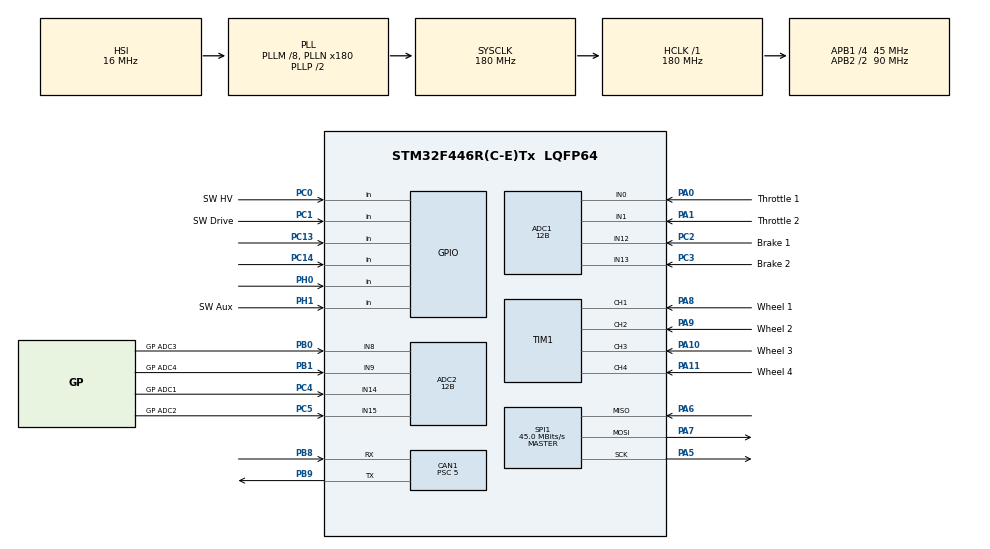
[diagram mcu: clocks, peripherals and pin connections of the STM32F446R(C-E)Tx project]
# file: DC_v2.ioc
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ADC1.Channel-52\#ChannelRegularConversion=ADC_CHANNEL_0
ADC1.Channel-53\#ChannelRegularConversion=ADC_CHANNEL_1
ADC1.Channel-54\#ChannelRegularConversion=ADC_CHANNEL_12
ADC1.Channel-55\#ChannelRegularConversion=ADC_CHANNEL_13
ADC1.ClockPrescaler=ADC_CLOCK_SYNC_PCLK_DIV4
ADC1.ContinuousConvMode=ENABLE
ADC1.DMAContinuousRequests=ENABLE
ADC1.DataAlign=ADC_DATAALIGN_RIGHT
ADC1.DiscontinuousConvMode=DISABLE
ADC1.EOCSelection=ADC_EOC_SEQ_CONV
ADC1.EnableAnalogWatchDog=false
ADC1.ExternalTrigConv=ADC_SOFTWARE_START
ADC1.ExternalTrigConvEdge=ADC_EXTERNALTRIGCONVEDGE_NONE
ADC1.InjNumberOfConversion=0
ADC1.NbrOfConversion=4
ADC1.NbrOfConversionFlag=1
ADC1.Rank-52\#ChannelRegularConversion=1
ADC1.Rank-53\#ChannelRegularConversion=2
ADC1.Rank-54\#ChannelRegularConversion=3
ADC1.Rank-55\#ChannelRegularConversion=4
ADC1.Resolution=ADC_RESOLUTION_12B
ADC1.SamplingTime-52\#ChannelRegularConversion=ADC_SAMPLETIME_3CYCLES
ADC1.SamplingTime-53\#ChannelRegularConversion=ADC_SAMPLETIME_3CYCLES
ADC1.SamplingTime-54\#ChannelRegularConversion=ADC_SAMPLETIME_3CYCLES
ADC1.SamplingTime-55\#ChannelRegularConversion=ADC_SAMPLETIME_3CYCLES
ADC1.ScanConvMode=ENABLE
ADC1.master=1
ADC2.Channel-152\#ChannelRegularConversion=ADC_CHANNEL_8
ADC2.ClockPrescaler=ADC_CLOCK_SYNC_PCLK_DIV4
ADC2.ContinuousConvMode=DISABLE
ADC2.DMAContinuousRequests=DISABLE
ADC2.DataAlign=ADC_DATAALIGN_RIGHT
ADC2.DiscontinuousConvMode=DISABLE
ADC2.EOCSelection=ADC_EOC_SINGLE_CONV
ADC2.EnableAnalogWatchDog=false
ADC2.ExternalTrigConv=ADC_SOFTWARE_START
ADC2.ExternalTrigConvEdge=ADC_EXTERNALTRIGCONVEDGE_NONE
ADC2.InjNumberOfConversion=0
ADC2.NbrOfConversion=1
ADC2.NbrOfConversionFlag=1
ADC2.Rank-152\#ChannelRegularConversion=1
ADC2.Resolution=ADC_RESOLUTION_12B
ADC2.SamplingTime-152\#ChannelRegularConversion=ADC_SAMPLETIME_3CYCLES
ADC2.ScanConvMode=DISABLE
CAN1.BS1=CAN_BS1_15TQ
CAN1.BS2=CAN_BS2_2TQ
CAN1.CalculateTimeBit=2000
CAN1.CalculateTimeQuantum=111.11111111111111
CAN1.Prescaler=5
Dma.ADC1.0.Direction=DMA_PERIPH_TO_MEMORY
Dma.ADC1.0.FIFOMode=DMA_FIFOMODE_DISABLE
Dma.ADC1.0.Instance=DMA2_Stream0
Dma.ADC1.0.MemDataAlignment=DMA_MDATAALIGN_HALFWORD
Dma.ADC1.0.MemInc=DMA_MINC_ENABLE
Dma.ADC1.0.Mode=DMA_CIRCULAR
Dma.ADC1.0.PeriphDataAlignment=DMA_PDATAALIGN_HALFWORD
Dma.ADC1.0.PeriphInc=DMA_PINC_DISABLE
Dma.ADC1.0.Priority=DMA_PRIORITY_HIGH
Dma.Request0=ADC1
FREERTOS.Tasks01=defaultTask,-3,128,StartDefaultTask,Default,NULL,Dynamic,NULL,NULL
Mcu.Family=STM32F4
Mcu.Name=STM32F446R(C-E)Tx
Mcu.Package=LQFP64
NVIC.DMA2_Stream0_IRQn=true\:5\:0\:false\:false\:true\:true
NVIC.PriorityGroup=NVIC_PRIORITYGROUP_4
PA0-WKUP.GPIO_Label=Throttle 1
PA0-WKUP.Signal=ADCx_IN0
PA1.GPIO_Label=Throttle 2
PA1.Signal=ADCx_IN1
PA10.GPIO_Label=Wheel 3
PA10.Signal=S_TIM1_CH3
PA11.GPIO_Label=Wheel 4
PA11.Signal=S_TIM1_CH4
PA5.Mode=Full_Duplex_Master
PA5.Signal=SPI1_SCK
PA6.Mode=Full_Duplex_Master
PA6.Signal=SPI1_MISO
PA7.Mode=Full_Duplex_Master
PA7.Signal=SPI1_MOSI
PA8.GPIO_Label=Wheel 1
PA8.Signal=S_TIM1_CH1
PA9.GPIO_Label=Wheel 2
PA9.Signal=S_TIM1_CH2
PB0.GPIO_Label=GP ADC3
PB0.Signal=ADCx_IN8
PB1.GPIO_Label=GP ADC4
PB1.Signal=ADCx_IN9
PB8.Mode=Master
PB8.Signal=CAN1_RX
PB9.Mode=Master
PB9.Signal=CAN1_TX
PC0.GPIO_Label=SW HV
PC0.Signal=GPIO_Input
PC1.GPIO_Label=SW Drive
PC1.Signal=GPIO_Input
PC13.Signal=GPIO_Input
PC14-OSC32_IN.Signal=GPIO_Input
PC2.GPIO_Label=Brake 1
PC2.Signal=ADCx_IN12
PC3.GPIO_Label=Brake 2
PC3.Signal=ADCx_IN13
PC4.GPIO_Label=GP ADC1
PC4.Signal=ADCx_IN14
PC5.GPIO_Label=GP ADC2
PC5.Signal=ADCx_IN15
PH0-OSC_IN.Signal=GPIO_Input
PH1-OSC_OUT.GPIO_Label=SW Aux
PH1-OSC_OUT.GPIO_Mode=GPIO_MODE_INPUT
PH1-OSC_OUT.GPIO_PuPd=GPIO_NOPULL
PH1-OSC_OUT.Signal=GPIO_Input
ProjectManager.HeapSize=0x200
ProjectManager.StackSize=0x400
ProjectManager.TargetToolchain=SW4STM32
RCC.AHBFreq_Value=180000000
RCC.APB1CLKDivider=RCC_HCLK_DIV4
RCC.APB1Freq_Value=45000000
RCC.APB1TimFreq_Value=90000000
RCC.APB2CLKDivider=RCC_HCLK_DIV2
RCC.APB2Freq_Value=90000000
RCC.APB2TimFreq_Value=180000000
RCC.CortexFreq_Value=180000000
RCC.HCLKFreq_Value=180000000
RCC.PLLM=8
RCC.PLLN=180
RCC.SYSCLKFreq_VALUE=180000000
RCC.SYSCLKSource=RCC_SYSCLKSOURCE_PLLCLK
RCC.USBFreq_Value=180000000
RCC.VCOOutputFreq_Value=360000000
SH.ADCx_IN0.0=ADC1_IN0,IN0
SH.ADCx_IN1.0=ADC1_IN1,IN1
SH.ADCx_IN12.0=ADC1_IN12,IN12
SH.ADCx_IN13.0=ADC1_IN13,IN13
SH.ADCx_IN14.0=ADC2_IN14,IN14
SH.ADCx_IN15.0=ADC2_IN15,IN15
SH.ADCx_IN8.0=ADC2_IN8,IN8
SH.ADCx_IN9.0=ADC2_IN9,IN9
SH.S_TIM1_CH1.0=TIM1_CH1,Input_Capture1_from_TI1
SH.S_TIM1_CH2.0=TIM1_CH2,Input_Capture2_from_TI2
SH.S_TIM1_CH3.0=TIM1_CH3,Input_Capture3_from_TI3
SH.S_TIM1_CH4.0=TIM1_CH4,Input_Capture4_from_TI4
SPI1.CalculateBaudRate=45.0 MBits/s
SPI1.Direction=SPI_DIRECTION_2LINES
SPI1.Mode=SPI_MODE_MASTER
SPI1.VirtualType=VM_MASTER
TIM1.Channel-Input_Capture1_from_TI1=TIM_CHANNEL_1
TIM1.Channel-Input_Capture2_from_TI2=TIM_CHANNEL_2
TIM1.Channel-Input_Capture3_from_TI3=TIM_CHANNEL_3
TIM1.Channel-Input_Capture4_from_TI4=TIM_CHANNEL_4
VP_FREERTOS_VS_ENABLE.Mode=Enabled
board=DC_v2

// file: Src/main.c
/**
  ******************************************************************************
  * File Name          : main.c
  * Description        : Main program body
  ******************************************************************************
  * This notice applies to any and all portions of this file
  * that are not between comment pairs USER CODE BEGIN and
  * USER CODE END. Other portions of this file, whether
  * inserted by the user or by software development tools
  * are owned by their respective copyright owners.
  *
  * Copyright (c) 2017 STMicroelectronics International N.V.
  * All rights reserved.
  *
  * Redistribution and use in source and binary forms, with or without
  * modification, are permitted, provided that the following conditions are met:
  *
  * 1. Redistribution of source code must retain the above copyright notice,
  *    this list of conditions and the following disclaimer.
  * 2. Redistributions in binary form must reproduce the above copyright notice,
  *    this list of conditions and the following disclaimer in the documentation
  *    and/or other materials provided with the distribution.
  * 3. Neither the name of STMicroelectronics nor the names of other
  *    contributors to this software may be used to endorse or promote products
  *    derived from this software without specific written permission.
  * 4. This software, including modifications and/or derivative works of this
  *    software, must execute solely and exclusively on microcontroller or
  *    microprocessor devices manufactured by or for STMicroelectronics.
  * 5. Redistribution and use of this software other than as permitted under
  *    this license is void and will automatically terminate your rights under
  *    this license.
  *
  * THIS SOFTWARE IS PROVIDED BY STMICROELECTRONICS AND CONTRIBUTORS "AS IS"
  * AND ANY EXPRESS, IMPLIED OR STATUTORY WARRANTIES, INCLUDING, BUT NOT
  * LIMITED TO, THE IMPLIED WARRANTIES OF MERCHANTABILITY, FITNESS FOR A
  * PARTICULAR PURPOSE AND NON-INFRINGEMENT OF THIRD PARTY INTELLECTUAL PROPERTY
  * RIGHTS ARE DISCLAIMED TO THE FULLEST EXTENT PERMITTED BY LAW. IN NO EVENT
  * SHALL STMICROELECTRONICS OR CONTRIBUTORS BE LIABLE FOR ANY DIRECT, INDIRECT,
  * INCIDENTAL, SPECIAL, EXEMPLARY, OR CONSEQUENTIAL DAMAGES (INCLUDING, BUT NOT
  * LIMITED TO, PROCUREMENT OF SUBSTITUTE GOODS OR SERVICES; LOSS OF USE, DATA,
  * OR PROFITS; OR BUSINESS INTERRUPTION) HOWEVER CAUSED AND ON ANY THEORY OF
  * LIABILITY, WHETHER IN CONTRACT, STRICT LIABILITY, OR TORT (INCLUDING
  * NEGLIGENCE OR OTHERWISE) ARISING IN ANY WAY OUT OF THE USE OF THIS SOFTWARE,
  * EVEN IF ADVISED OF THE POSSIBILITY OF SUCH DAMAGE.
  *
  ******************************************************************************
  */
#include "main.h"
#include "stm32f4xx_hal.h"
#include "cmsis_os.h"

/* USER CODE BEGIN Includes */
#include "debug.h"
#include "pedal.h"
/* USER CODE END Includes */

ADC_HandleTypeDef hadc1;
ADC_HandleTypeDef hadc2;
DMA_HandleTypeDef hdma_adc1;

CAN_HandleTypeDef hcan1;

SPI_HandleTypeDef hspi1;

TIM_HandleTypeDef htim1;

osThreadId defaultTaskHandle;

/* USER CODE BEGIN PV */
/* Private variables ---------------------------------------------------------*/

/* USER CODE END PV */

void SystemClock_Config(void);
static void MX_GPIO_Init(void);
static void MX_DMA_Init(void);
static void MX_ADC1_Init(void);
static void MX_ADC2_Init(void);
static void MX_CAN1_Init(void);
static void MX_SPI1_Init(void);
static void MX_TIM1_Init(void);
void StartDefaultTask(void const * argument);

/* USER CODE BEGIN PFP */
/* Private function prototypes -----------------------------------------------*/

/* USER CODE END PFP */

int main(void)
{

  /* MCU Configuration----------------------------------------------------------*/

  /* Reset of all peripherals, Initializes the Flash interface and the Systick. */
  HAL_Init();

  /* Configure the system clock */
  SystemClock_Config();

  /* Initialize all configured peripherals */
  MX_GPIO_Init();
  MX_DMA_Init();
  MX_ADC1_Init();
  MX_ADC2_Init();
  MX_CAN1_Init();
  MX_SPI1_Init();
  MX_TIM1_Init();

  /* USER CODE BEGIN 2 */
  debug_init();
//  pedal_init();
  debug_log("<<< Init Finished >>>");
  /* USER CODE END 2 */

  /* Create the thread(s) */
  /* definition and creation of defaultTask */
  osThreadDef(defaultTask, StartDefaultTask, osPriorityIdle, 0, 128);
  defaultTaskHandle = osThreadCreate(osThread(defaultTask), NULL);

  /* USER CODE BEGIN RTOS_THREADS */
  /* add threads, ... */
//  osThreadDef(pedalTask, pedal_debug, osPriorityNormal, 0, 128);
//  osThreadCreate(osThread(pedalTask), NULL);
  /* USER CODE END RTOS_THREADS */

  /* Start scheduler */
  osKernelStart();

  /* We should never get here as control is now taken by the scheduler */

  /* Infinite loop */
  while (1)
  {

  }

}

/** System Clock Configuration
*/
void SystemClock_Config(void)
{

  RCC_OscInitTypeDef RCC_OscInitStruct;
  RCC_ClkInitTypeDef RCC_ClkInitStruct;

    /**Configure the main internal regulator output voltage
    */
  __HAL_RCC_PWR_CLK_ENABLE();

  __HAL_PWR_VOLTAGESCALING_CONFIG(PWR_REGULATOR_VOLTAGE_SCALE1);

    /**Initializes the CPU, AHB and APB busses clocks
    */
  RCC_OscInitStruct.OscillatorType = RCC_OSCILLATORTYPE_HSI;
  RCC_OscInitStruct.HSIState = RCC_HSI_ON;
  RCC_OscInitStruct.HSICalibrationValue = 16;
  RCC_OscInitStruct.PLL.PLLState = RCC_PLL_ON;
  RCC_OscInitStruct.PLL.PLLSource = RCC_PLLSOURCE_HSI;
  RCC_OscInitStruct.PLL.PLLM = 8;
  RCC_OscInitStruct.PLL.PLLN = 180;
  RCC_OscInitStruct.PLL.PLLP = RCC_PLLP_DIV2;
  RCC_OscInitStruct.PLL.PLLQ = 2;
  RCC_OscInitStruct.PLL.PLLR = 2;
  if (HAL_RCC_OscConfig(&RCC_OscInitStruct) != HAL_OK)
  {
    _Error_Handler(__FILE__, __LINE__);
  }

    /**Activate the Over-Drive mode
    */
  if (HAL_PWREx_EnableOverDrive() != HAL_OK)
  {
    _Error_Handler(__FILE__, __LINE__);
  }

    /**Initializes the CPU, AHB and APB busses clocks
    */
  RCC_ClkInitStruct.ClockType = RCC_CLOCKTYPE_HCLK|RCC_CLOCKTYPE_SYSCLK
                              |RCC_CLOCKTYPE_PCLK1|RCC_CLOCKTYPE_PCLK2;
  RCC_ClkInitStruct.SYSCLKSource = RCC_SYSCLKSOURCE_PLLCLK;
  RCC_ClkInitStruct.AHBCLKDivider = RCC_SYSCLK_DIV1;
  RCC_ClkInitStruct.APB1CLKDivider = RCC_HCLK_DIV4;
  RCC_ClkInitStruct.APB2CLKDivider = RCC_HCLK_DIV2;

  if (HAL_RCC_ClockConfig(&RCC_ClkInitStruct, FLASH_LATENCY_5) != HAL_OK)
  {
    _Error_Handler(__FILE__, __LINE__);
  }

    /**Configure the Systick interrupt time
    */
  HAL_SYSTICK_Config(HAL_RCC_GetHCLKFreq()/1000);

    /**Configure the Systick
    */
  HAL_SYSTICK_CLKSourceConfig(SYSTICK_CLKSOURCE_HCLK);

  /* SysTick_IRQn interrupt configuration */
  HAL_NVIC_SetPriority(SysTick_IRQn, 15, 0);
}

/* ADC1 init function */
static void MX_ADC1_Init(void)
{

  ADC_ChannelConfTypeDef sConfig;

    /**Configure the global features of the ADC (Clock, Resolution, Data Alignment and number of conversion)
    */
  hadc1.Instance = ADC1;
  hadc1.Init.ClockPrescaler = ADC_CLOCK_SYNC_PCLK_DIV4;
  hadc1.Init.Resolution = ADC_RESOLUTION_12B;
  hadc1.Init.ScanConvMode = ENABLE;
  hadc1.Init.ContinuousConvMode = ENABLE;
  hadc1.Init.DiscontinuousConvMode = DISABLE;
  hadc1.Init.ExternalTrigConvEdge = ADC_EXTERNALTRIGCONVEDGE_NONE;
  hadc1.Init.ExternalTrigConv = ADC_SOFTWARE_START;
  hadc1.Init.DataAlign = ADC_DATAALIGN_RIGHT;
  hadc1.Init.NbrOfConversion = 4;
  hadc1.Init.DMAContinuousRequests = ENABLE;
  hadc1.Init.EOCSelection = ADC_EOC_SEQ_CONV;
  if (HAL_ADC_Init(&hadc1) != HAL_OK)
  {
    _Error_Handler(__FILE__, __LINE__);
  }

    /**Configure for the selected ADC regular channel its corresponding rank in the sequencer and its sample time.
    */
  sConfig.Channel = ADC_CHANNEL_0;
  sConfig.Rank = 1;
  sConfig.SamplingTime = ADC_SAMPLETIME_3CYCLES;
  if (HAL_ADC_ConfigChannel(&hadc1, &sConfig) != HAL_OK)
  {
    _Error_Handler(__FILE__, __LINE__);
  }

    /**Configure for the selected ADC regular channel its corresponding rank in the sequencer and its sample time.
    */
  sConfig.Channel = ADC_CHANNEL_1;
  sConfig.Rank = 2;
  if (HAL_ADC_ConfigChannel(&hadc1, &sConfig) != HAL_OK)
  {
    _Error_Handler(__FILE__, __LINE__);
  }

    /**Configure for the selected ADC regular channel its corresponding rank in the sequencer and its sample time.
    */
  sConfig.Channel = ADC_CHANNEL_12;
  sConfig.Rank = 3;
  if (HAL_ADC_ConfigChannel(&hadc1, &sConfig) != HAL_OK)
  {
    _Error_Handler(__FILE__, __LINE__);
  }

    /**Configure for the selected ADC regular channel its corresponding rank in the sequencer and its sample time.
    */
  sConfig.Channel = ADC_CHANNEL_13;
  sConfig.Rank = 4;
  if (HAL_ADC_ConfigChannel(&hadc1, &sConfig) != HAL_OK)
  {
    _Error_Handler(__FILE__, __LINE__);
  }

}

/* ADC2 init function */
static void MX_ADC2_Init(void)
{

  ADC_ChannelConfTypeDef sConfig;

    /**Configure the global features of the ADC (Clock, Resolution, Data Alignment and number of conversion)
    */
  hadc2.Instance = ADC2;
  hadc2.Init.ClockPrescaler = ADC_CLOCK_SYNC_PCLK_DIV4;
  hadc2.Init.Resolution = ADC_RESOLUTION_12B;
  hadc2.Init.ScanConvMode = DISABLE;
  hadc2.Init.ContinuousConvMode = DISABLE;
  hadc2.Init.DiscontinuousConvMode = DISABLE;
  hadc2.Init.ExternalTrigConvEdge = ADC_EXTERNALTRIGCONVEDGE_NONE;
  hadc2.Init.ExternalTrigConv = ADC_SOFTWARE_START;
  hadc2.Init.DataAlign = ADC_DATAALIGN_RIGHT;
  hadc2.Init.NbrOfConversion = 1;
  hadc2.Init.DMAContinuousRequests = DISABLE;
  hadc2.Init.EOCSelection = ADC_EOC_SINGLE_CONV;
  if (HAL_ADC_Init(&hadc2) != HAL_OK)
  {
    _Error_Handler(__FILE__, __LINE__);
  }

    /**Configure for the selected ADC regular channel its corresponding rank in the sequencer and its sample time.
    */
  sConfig.Channel = ADC_CHANNEL_8;
  sConfig.Rank = 1;
  sConfig.SamplingTime = ADC_SAMPLETIME_3CYCLES;
  if (HAL_ADC_ConfigChannel(&hadc2, &sConfig) != HAL_OK)
  {
    _Error_Handler(__FILE__, __LINE__);
  }

}

/* CAN1 init function */
static void MX_CAN1_Init(void)
{

  hcan1.Instance = CAN1;
  hcan1.Init.Prescaler = 5;
  hcan1.Init.Mode = CAN_MODE_NORMAL;
  hcan1.Init.SJW = CAN_SJW_1TQ;
  hcan1.Init.BS1 = CAN_BS1_15TQ;
  hcan1.Init.BS2 = CAN_BS2_2TQ;
  hcan1.Init.TTCM = DISABLE;
  hcan1.Init.ABOM = DISABLE;
  hcan1.Init.AWUM = DISABLE;
  hcan1.Init.NART = DISABLE;
  hcan1.Init.RFLM = DISABLE;
  hcan1.Init.TXFP = DISABLE;
  if (HAL_CAN_Init(&hcan1) != HAL_OK)
  {
    _Error_Handler(__FILE__, __LINE__);
  }

}

/* SPI1 init function */
static void MX_SPI1_Init(void)
{

  hspi1.Instance = SPI1;
  hspi1.Init.Mode = SPI_MODE_MASTER;
  hspi1.Init.Direction = SPI_DIRECTION_2LINES;
  hspi1.Init.DataSize = SPI_DATASIZE_8BIT;
  hspi1.Init.CLKPolarity = SPI_POLARITY_LOW;
  hspi1.Init.CLKPhase = SPI_PHASE_1EDGE;
  hspi1.Init.NSS = SPI_NSS_SOFT;
  hspi1.Init.BaudRatePrescaler = SPI_BAUDRATEPRESCALER_2;
  hspi1.Init.FirstBit = SPI_FIRSTBIT_MSB;
  hspi1.Init.TIMode = SPI_TIMODE_DISABLE;
  hspi1.Init.CRCCalculation = SPI_CRCCALCULATION_DISABLE;
  hspi1.Init.CRCPolynomial = 10;
  if (HAL_SPI_Init(&hspi1) != HAL_OK)
  {
    _Error_Handler(__FILE__, __LINE__);
  }

}

/* TIM1 init function */
static void MX_TIM1_Init(void)
{

  TIM_MasterConfigTypeDef sMasterConfig;
  TIM_IC_InitTypeDef sConfigIC;

  htim1.Instance = TIM1;
  htim1.Init.Prescaler = 0;
  htim1.Init.CounterMode = TIM_COUNTERMODE_UP;
  htim1.Init.Period = 0;
  htim1.Init.ClockDivision = TIM_CLOCKDIVISION_DIV1;
  htim1.Init.RepetitionCounter = 0;
  if (HAL_TIM_IC_Init(&htim1) != HAL_OK)
  {
    _Error_Handler(__FILE__, __LINE__);
  }

  sMasterConfig.MasterOutputTrigger = TIM_TRGO_RESET;
  sMasterConfig.MasterSlaveMode = TIM_MASTERSLAVEMODE_DISABLE;
  if (HAL_TIMEx_MasterConfigSynchronization(&htim1, &sMasterConfig) != HAL_OK)
  {
    _Error_Handler(__FILE__, __LINE__);
  }

  sConfigIC.ICPolarity = TIM_INPUTCHANNELPOLARITY_RISING;
  sConfigIC.ICSelection = TIM_ICSELECTION_DIRECTTI;
  sConfigIC.ICPrescaler = TIM_ICPSC_DIV1;
  sConfigIC.ICFilter = 0;
  if (HAL_TIM_IC_ConfigChannel(&htim1, &sConfigIC, TIM_CHANNEL_1) != HAL_OK)
  {
    _Error_Handler(__FILE__, __LINE__);
  }

  if (HAL_TIM_IC_ConfigChannel(&htim1, &sConfigIC, TIM_CHANNEL_2) != HAL_OK)
  {
    _Error_Handler(__FILE__, __LINE__);
  }

  if (HAL_TIM_IC_ConfigChannel(&htim1, &sConfigIC, TIM_CHANNEL_3) != HAL_OK)
  {
    _Error_Handler(__FILE__, __LINE__);
  }

  if (HAL_TIM_IC_ConfigChannel(&htim1, &sConfigIC, TIM_CHANNEL_4) != HAL_OK)
  {
    _Error_Handler(__FILE__, __LINE__);
  }

}

static void MX_DMA_Init(void)
{
  /* DMA controller clock enable */
  __HAL_RCC_DMA2_CLK_ENABLE();

  /* DMA interrupt init */
  /* DMA2_Stream0_IRQn interrupt configuration */
  HAL_NVIC_SetPriority(DMA2_Stream0_IRQn, 5, 0);
  HAL_NVIC_EnableIRQ(DMA2_Stream0_IRQn);

}

/** Configure pins as
        * Analog
        * Input
        * Output
        * EVENT_OUT
        * EXTI
*/
static void MX_GPIO_Init(void)
{

  GPIO_InitTypeDef GPIO_InitStruct;

  /* GPIO Ports Clock Enable */
  __HAL_RCC_GPIOC_CLK_ENABLE();
  __HAL_RCC_GPIOH_CLK_ENABLE();
  __HAL_RCC_GPIOA_CLK_ENABLE();
  __HAL_RCC_GPIOB_CLK_ENABLE();

  /*Configure GPIO pins : PC13 PC14 SW_HV_Pin SW_Drive_Pin */
  GPIO_InitStruct.Pin = GPIO_PIN_13|GPIO_PIN_14|SW_HV_Pin|SW_Drive_Pin;
  GPIO_InitStruct.Mode = GPIO_MODE_INPUT;
  GPIO_InitStruct.Pull = GPIO_NOPULL;
  HAL_GPIO_Init(GPIOC, &GPIO_InitStruct);

  /*Configure GPIO pins : PH0 SW_Aux_Pin */
  GPIO_InitStruct.Pin = GPIO_PIN_0|SW_Aux_Pin;
  GPIO_InitStruct.Mode = GPIO_MODE_INPUT;
  GPIO_InitStruct.Pull = GPIO_NOPULL;
  HAL_GPIO_Init(GPIOH, &GPIO_InitStruct);

}

/* StartDefaultTask function */
void StartDefaultTask(void const * argument)
{

  for(;;)
  {
    osDelay(1);
  }
}

void _Error_Handler(char * file, int line)
{
  /* USER CODE BEGIN Error_Handler_Debug */
  /* User can add his own implementation to report the HAL error return state */
  debug_log("[Critical Error]: %s:%d", file, line);
  while(1)
  {
  }
  /* USER CODE END Error_Handler_Debug */
}

/************************ (C) COPYRIGHT STMicroelectronics *****END OF FILE****/
